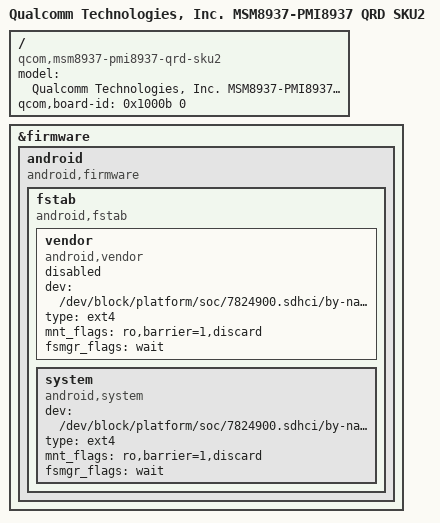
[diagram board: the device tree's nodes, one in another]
/*
 * Copyright (c) 2015-2016, The Linux Foundation. All rights reserved.
 *
 * Copyright (c) 2020, Shubham-Panwar. All rights reserved.
 *
 * This program is free software; you can redistribute it and/or modify
 * it under the terms of the GNU General Public License version 2 and
 * only version 2 as published by the Free Software Foundation.
 *
 * This program is distributed in the hope that it will be useful,
 * but WITHOUT ANY WARRANTY; without even the implied warranty of
 * MERCHANTABILITY or FITNESS FOR A PARTICULAR PURPOSE.  See the
 * GNU General Public License for more details.
 */

/dts-v1/;


#include "msm8937.dtsi"
#include "msm-pmi8937.dtsi"
#include "msm8937-qrd.dtsi"
#include "msm8937-mdss-panels.dtsi"

/ {
	model = "Qualcomm Technologies, Inc. MSM8937-PMI8937 QRD SKU2";
	compatible = "qcom,msm8937-pmi8937-qrd-sku2",
		   "qcom,msm8937-qrd", "qcom,msm8937", "qcom,qrd";
	qcom,board-id= <0x1000b 0>;
};


#include "holland1/holland1.dtsi"


&firmware {

	android {
		compatible = "android,firmware";

		fstab {
			compatible = "android,fstab";

			vendor {
				compatible = "android,vendor";
				dev = "/dev/block/platform/soc/7824900.sdhci/by-name/vendor";
				type = "ext4";
				mnt_flags = "ro,barrier=1,discard";
				fsmgr_flags = "wait";
				status = "disabled";
				};

			system {
				compatible = "android,system";
				dev = "/dev/block/platform/soc/7824900.sdhci/by-name/system";
				type = "ext4";
				mnt_flags = "ro,barrier=1,discard";
				fsmgr_flags = "wait";
				status = "ok";
			};
		};
	};
};
